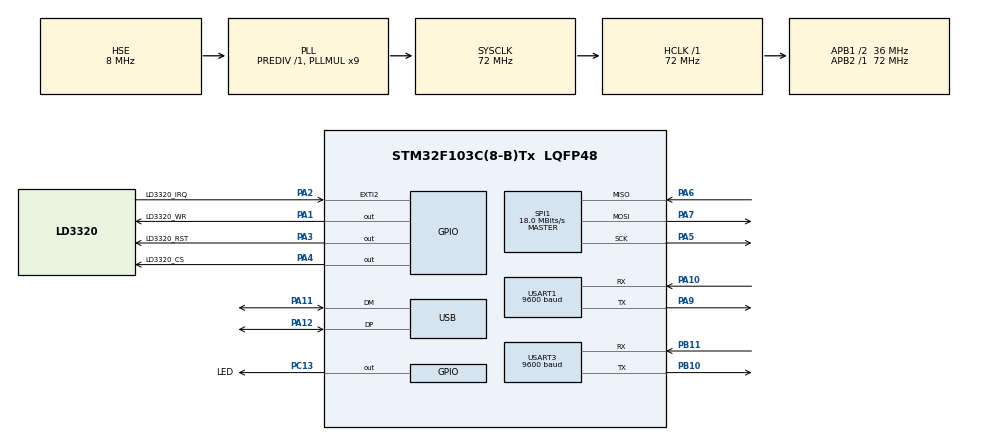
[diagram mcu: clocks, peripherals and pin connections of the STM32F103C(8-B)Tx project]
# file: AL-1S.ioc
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Mcu.Family=STM32F1
Mcu.Name=STM32F103C(8-B)Tx
Mcu.Package=LQFP48
NVIC.EXTI2_IRQn=true\:5\:0\:true\:false\:true\:true\:true\:true
NVIC.PriorityGroup=NVIC_PRIORITYGROUP_4
NVIC.RCC_IRQn=true\:0\:0\:false\:false\:true\:true\:false\:true
NVIC.USART3_IRQn=true\:0\:0\:false\:false\:true\:true\:true\:true
NVIC.USB_HP_CAN1_TX_IRQn=true\:0\:0\:false\:false\:true\:true\:true\:true
NVIC.USB_LP_CAN1_RX0_IRQn=true\:0\:0\:false\:false\:true\:true\:true\:true
PA1.GPIO_Label=LD3320_WR
PA1.GPIO_PuPd=GPIO_PULLUP
PA1.GPIO_Speed=GPIO_SPEED_FREQ_LOW
PA1.PinState=GPIO_PIN_SET
PA1.Signal=GPIO_Output
PA10.Mode=Asynchronous
PA10.Signal=USART1_RX
PA11.Mode=Device
PA11.Signal=USB_DM
PA12.Mode=Device
PA12.Signal=USB_DP
PA13.Mode=Serial_Wire
PA13.Signal=SYS_JTMS-SWDIO
PA14.Mode=Serial_Wire
PA14.Signal=SYS_JTCK-SWCLK
PA2.GPIO_Label=LD3320_IRQ
PA2.GPIO_ModeDefaultEXTI=GPIO_MODE_IT_FALLING
PA2.GPIO_PuPd=GPIO_PULLUP
PA2.Signal=GPXTI2
PA3.GPIO_Label=LD3320_RST
PA3.GPIO_PuPd=GPIO_PULLUP
PA3.PinState=GPIO_PIN_SET
PA3.Signal=GPIO_Output
PA4.GPIO_Label=LD3320_CS
PA4.GPIO_PuPd=GPIO_PULLUP
PA4.PinState=GPIO_PIN_SET
PA4.Signal=GPIO_Output
PA5.Mode=Full_Duplex_Master
PA5.Signal=SPI1_SCK
PA6.Mode=Full_Duplex_Master
PA6.Signal=SPI1_MISO
PA7.Mode=Full_Duplex_Master
PA7.Signal=SPI1_MOSI
PA9.Mode=Asynchronous
PA9.Signal=USART1_TX
PB10.Mode=Asynchronous
PB10.Signal=USART3_TX
PB11.Mode=Asynchronous
PB11.Signal=USART3_RX
PC13-TAMPER-RTC.GPIO_Label=LED
PC13-TAMPER-RTC.GPIO_PuPd=GPIO_PULLUP
PC13-TAMPER-RTC.PinState=GPIO_PIN_SET
PC13-TAMPER-RTC.Signal=GPIO_Output
PD0-OSC_IN.Mode=HSE-External-Oscillator
PD0-OSC_IN.Signal=RCC_OSC_IN
PD1-OSC_OUT.Mode=HSE-External-Oscillator
PD1-OSC_OUT.Signal=RCC_OSC_OUT
ProjectManager.HeapSize=0x200
ProjectManager.StackSize=0x400
ProjectManager.TargetToolchain=STM32CubeIDE
RCC.AHBFreq_Value=72000000
RCC.APB1CLKDivider=RCC_HCLK_DIV2
RCC.APB1Freq_Value=36000000
RCC.APB1TimFreq_Value=72000000
RCC.APB2Freq_Value=72000000
RCC.APB2TimFreq_Value=72000000
RCC.HCLKFreq_Value=72000000
RCC.PLLMUL=RCC_PLL_MUL9
RCC.SYSCLKFreq_VALUE=72000000
RCC.SYSCLKSource=RCC_SYSCLKSOURCE_PLLCLK
RCC.USBFreq_Value=48000000
RCC.USBPrescaler=RCC_USBCLKSOURCE_PLL_DIV1_5
SPI1.BaudRatePrescaler=SPI_BAUDRATEPRESCALER_4
SPI1.CLKPolarity=SPI_POLARITY_HIGH
SPI1.CalculateBaudRate=18.0 MBits/s
SPI1.Direction=SPI_DIRECTION_2LINES
SPI1.Mode=SPI_MODE_MASTER
SPI1.VirtualType=VM_MASTER
USART1.BaudRate=9600
USART1.VirtualMode=VM_ASYNC
USART3.BaudRate=9600
USART3.VirtualMode=VM_ASYNC
USB_DEVICE.CLASS_NAME_FS=CDC
USB_DEVICE.VirtualMode=Cdc
USB_DEVICE.VirtualModeFS=Cdc_FS
VP_USB_DEVICE_VS_USB_DEVICE_CDC_FS.Mode=CDC_FS
board=custom

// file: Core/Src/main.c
/* USER CODE BEGIN Header */
/**
  ******************************************************************************
  * @file           : main.c
  * @brief          : Main program body
  ******************************************************************************
  * @attention
  *
  * Copyright (c) 2025 STMicroelectronics.
  * All rights reserved.
  *
  * This software is licensed under terms that can be found in the LICENSE file
  * in the root directory of this software component.
  * If no LICENSE file comes with this software, it is provided AS-IS.
  *
  ******************************************************************************
  */
/* USER CODE END Header */
#include "main.h"
#include "spi.h"
#include "usart.h"
#include "usb_device.h"
#include "gpio.h"
#include "LDChip.h"
#include "stdio.h"
#include <string.h>
/* USER CODE BEGIN Includes */
//extern void initialise_monitor_handles(void);
/* USER CODE END Includes */

void SystemClock_Config(void);

int MP3_reg = 0;
int main(void)
{
	//initialise_monitor_handles();

  /* MCU Configuration--------------------------------------------------------*/

  /* Reset of all peripherals, Initializes the Flash interface and the Systick. */
  HAL_Init();

  /* Configure the system clock */
  SystemClock_Config();

  /* Initialize all configured peripherals */
  MX_GPIO_Init();
  MX_SPI1_Init();
  MX_USART1_UART_Init();
  MX_USART3_UART_Init();
  MX_USB_DEVICE_Init();

  /* Infinite loop */
  /* USER CODE BEGIN WHILE */
  while (1)
  {
	  HAL_UART_Transmit(&huart1, (uint8_t*)"run LD3320 main\r\n",
	                                   strlen("run LD3320 main\r\n"), HAL_MAX_DELAY);

	  if (!MP3_reg) {
	  LD3320_main();
	  }
    /* USER CODE END WHILE */

  }
}

void SystemClock_Config(void)
{
  RCC_OscInitTypeDef RCC_OscInitStruct = {0};
  RCC_ClkInitTypeDef RCC_ClkInitStruct = {0};
  RCC_PeriphCLKInitTypeDef PeriphClkInit = {0};

  /** Initializes the RCC Oscillators according to the specified parameters
  * in the RCC_OscInitTypeDef structure.
  */
  RCC_OscInitStruct.OscillatorType = RCC_OSCILLATORTYPE_HSE;
  RCC_OscInitStruct.HSEState = RCC_HSE_ON;
  RCC_OscInitStruct.HSEPredivValue = RCC_HSE_PREDIV_DIV1;
  RCC_OscInitStruct.HSIState = RCC_HSI_ON;
  RCC_OscInitStruct.PLL.PLLState = RCC_PLL_ON;
  RCC_OscInitStruct.PLL.PLLSource = RCC_PLLSOURCE_HSE;
  RCC_OscInitStruct.PLL.PLLMUL = RCC_PLL_MUL9;
  if (HAL_RCC_OscConfig(&RCC_OscInitStruct) != HAL_OK)
  {
    Error_Handler();
  }

  /** Initializes the CPU, AHB and APB buses clocks
  */
  RCC_ClkInitStruct.ClockType = RCC_CLOCKTYPE_HCLK|RCC_CLOCKTYPE_SYSCLK
                              |RCC_CLOCKTYPE_PCLK1|RCC_CLOCKTYPE_PCLK2;
  RCC_ClkInitStruct.SYSCLKSource = RCC_SYSCLKSOURCE_PLLCLK;
  RCC_ClkInitStruct.AHBCLKDivider = RCC_SYSCLK_DIV1;
  RCC_ClkInitStruct.APB1CLKDivider = RCC_HCLK_DIV2;
  RCC_ClkInitStruct.APB2CLKDivider = RCC_HCLK_DIV1;

  if (HAL_RCC_ClockConfig(&RCC_ClkInitStruct, FLASH_LATENCY_2) != HAL_OK)
  {
    Error_Handler();
  }
  PeriphClkInit.PeriphClockSelection = RCC_PERIPHCLK_USB;
  PeriphClkInit.UsbClockSelection = RCC_USBCLKSOURCE_PLL_DIV1_5;
  if (HAL_RCCEx_PeriphCLKConfig(&PeriphClkInit) != HAL_OK)
  {
    Error_Handler();
  }
}

/* USER CODE BEGIN 4 */
void HAL_GPIO_EXTI_Callback(uint16_t GPIO_Pin)
{
    if(GPIO_Pin == GPIO_PIN_2){

    	LD_IRQHandler();
    }
}
/* USER CODE END 4 */

void Error_Handler(void)
{
  __disable_irq();
  while (1)
  {
  }
}
